# WDOGSAFE1 register map
Registers from a debugger description file.
Registers are 32-bit, write-only, no defined reset value unless marked. A register's access mark holds for its fields unless they carry their own. Addresses are absolute; registers are grouped by the start of their names; lines under a group give offsets from that group; [hi:lo] are bit positions; {n}, {i} and the like mark numbered series; 'fields as' and 'values as' point back to an identical list; <NAME> marks a mode.

## WDOGSAFE1
0x51003000 WDOGSAFE1/LoadMaxCount access not given
  [15:0] LoadMaxCount
0x51003004 WDOGSAFE1/CurrentMaxCount ro
  [15:0] CurrentMaxCount
0x51003008 WDOGSAFE1/LoadMinCount access not given
  [15:0] LoadMinCount
0x5100300C WDOGSAFE1/CurrentMinCount ro
  [15:0] CurrentMinCount
0x51003010 WDOGSAFE1/StatusInt0 ro
  [0] StatusInt0
0x51003014 WDOGSAFE1/StatusInt1 ro
  [0] StatusInt1
0x51003018 WDOGSAFE1/ClearInt ro
  [0] ClearInt
0x5100301C WDOGSAFE1/Control access not given
  [0] MaskInt
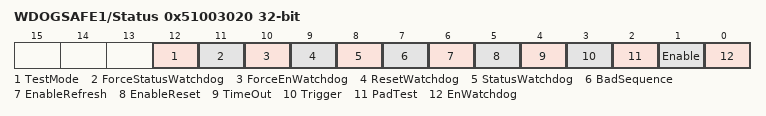
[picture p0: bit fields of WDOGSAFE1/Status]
0x51003020 WDOGSAFE1/Status ro
  [12] TestMode, [11] ForceStatusWatchdog, [10] ForceEnWatchdog, [9] ResetWatchdog, [8] StatusWatchdog, [7] BadSequence, [6] EnableRefresh, [5] EnableReset, [4] TimeOut, [3] Trigger, [2] PadTest, [1] Enable, [0] EnWatchdog
0x51003024 WDOGSAFE1/Refresh
  [31:0] Refresh
0x51003028 WDOGSAFE1/SetEnableRefresh
  [31:0] SetEnableRefresh
0x5100302C WDOGSAFE1/ClearEnableRefresh
  [31:0] ClearEnableRefresh
0x51003030 WDOGSAFE1/SetEnableReset
  [31:0] SetEnableReset
0x51003034 WDOGSAFE1/ClearEnableReset
  [31:0] ClearEnableReset
0x51003038 WDOGSAFE1/SetTrigger
  [31:0] SetTrigger
0x5100303C WDOGSAFE1/SetPadTest
  [31:0] SetPadTest
0x51003040 WDOGSAFE1/ClearPadTest
  [31:0] ClearPadTest
0x51003044 WDOGSAFE1/SetEnable
  [31:0] SetEnable
0x51003048 WDOGSAFE1/ClearEnable
  [31:0] ClearEnable
0x5100304C WDOGSAFE1/SetTestMode
  [31:0] SetTestMode
0x51003050 WDOGSAFE1/ClearTestMode
  [31:0] ClearTestMode
0x51003054 WDOGSAFE1/SetForceEnWatchdog
  [31:0] SetForceEnWatchdog
0x51003058 WDOGSAFE1/ClearForceEnWatchdog
  [31:0] ClearForceEnWatchdog
0x5100305C WDOGSAFE1/SetForceStatusWatchdog
  [31:0] SetForceStatusWatchdog
0x51003060 WDOGSAFE1/ClearForceStatusWatchdog
  [31:0] ClearForceStatusWatchdog
